AUTOSAR XML (schema 4-0-3)
package /ComponentTypes
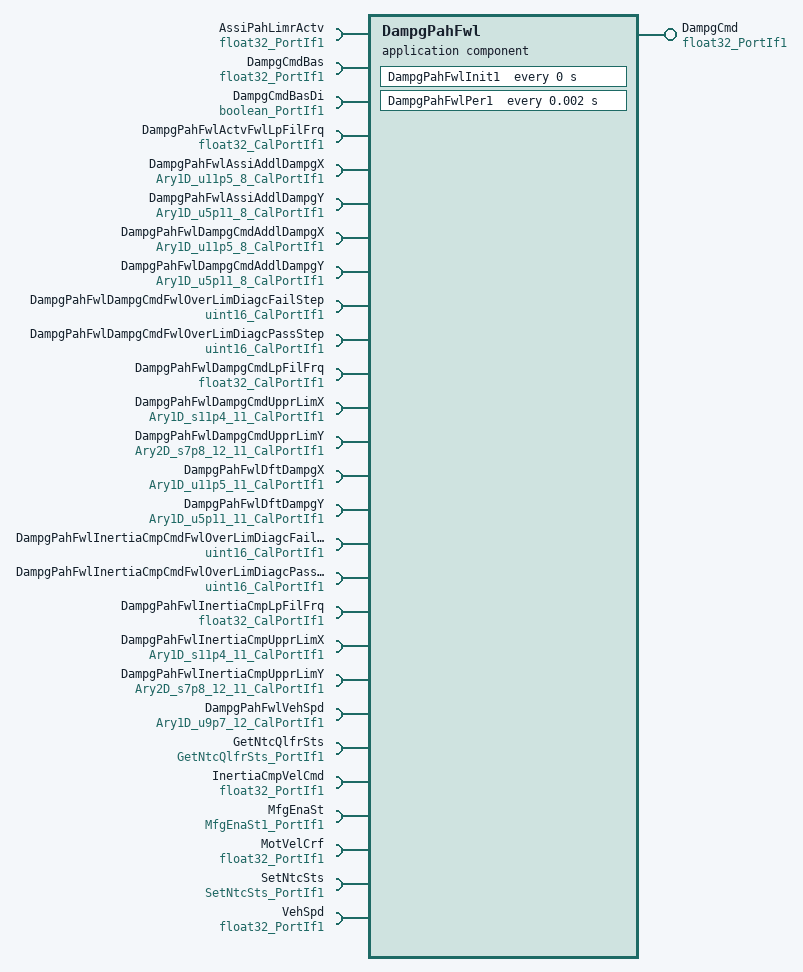
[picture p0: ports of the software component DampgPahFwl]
  application sw component type DampgPahFwl
    provide port DampgCmd: nonqueued-sender-com-spec{data-element=Val, init-value=0}, provided-interface=float32_PortIf1
    27 x require port:
      AssiPahLimrActv: nonqueued-receiver-com-spec{data-element=Val, filter=data-filter-type=ALWAYS, init-value=0}, required-interface=float32_PortIf1
      DampgCmdBas: nonqueued-receiver-com-spec{data-element=Val, filter=data-filter-type=ALWAYS, init-value=0}, required-interface=float32_PortIf1
      DampgCmdBasDi: nonqueued-receiver-com-spec{data-element=Logl, filter=data-filter-type=ALWAYS, init-value=0}, required-interface=boolean_PortIf1
      DampgPahFwlActvFwlLpFilFrq: parameter-require-com-spec{init-value=10, parameter=Val}, required-interface=float32_CalPortIf1
      DampgPahFwlAssiAddlDampgX: parameter-require-com-spec{init-value=[0, 3200, 6400, 9600, 12800, 25600, 32736, 35776], parameter=Ary1D}, required-interface=Ary1D_u11p5_8_CalPortIf1
      DampgPahFwlAssiAddlDampgY: parameter-require-com-spec{init-value=[0, 6144, 14336, 14336, 14336, 14336, 14336, 14336], parameter=Ary1D}, required-interface=Ary1D_u5p11_8_CalPortIf1
      DampgPahFwlDampgCmdAddlDampgX: parameter-require-com-spec{init-value=[0, 3200, 6400, 9600, 12800, 25600, 32736, 35776], parameter=Ary1D}, required-interface=Ary1D_u11p5_8_CalPortIf1
      DampgPahFwlDampgCmdAddlDampgY: parameter-require-com-spec{init-value=[0, 6144, 14336, 14336, 14336, 14336, 14336, 14336], parameter=Ary1D}, required-interface=Ary1D_u5p11_8_CalPortIf1
      DampgPahFwlDampgCmdFwlOverLimDiagcFailStep: parameter-require-com-spec{init-value=1311, parameter=Val}, required-interface=uint16_CalPortIf1
      DampgPahFwlDampgCmdFwlOverLimDiagcPassStep: parameter-require-com-spec{init-value=1311, parameter=Val}, required-interface=uint16_CalPortIf1
      DampgPahFwlDampgCmdLpFilFrq: parameter-require-com-spec{init-value=50, parameter=Val}, required-interface=float32_CalPortIf1
      DampgPahFwlDampgCmdUpprLimX: parameter-require-com-spec{init-value=[-9600, -1600, 0, 640, 1280, 1920, 3200, 4480, 5760, 7680, 9600], parameter=Ary1D}, required-interface=Ary1D_s11p4_11_CalPortIf1
      DampgPahFwlDampgCmdUpprLimY: parameter-require-com-spec{init-value=12 x 11 x 2253, parameter=Ary2D}, required-interface=Ary2D_s7p8_12_11_CalPortIf1
      DampgPahFwlDftDampgX: parameter-require-com-spec{init-value=[0, 1184, 2368, 3552, 4736, 5920, 7104, 8288, 9472, 10656, 11840], parameter=Ary1D}, required-interface=Ary1D_u11p5_11_CalPortIf1
      DampgPahFwlDftDampgY: parameter-require-com-spec{init-value=[0, 101, 232, 393, 586, 807, 1061, 1349, 1663, 2005, 2376], parameter=Ary1D}, required-interface=Ary1D_u5p11_11_CalPortIf1
      DampgPahFwlInertiaCmpCmdFwlOverLimDiagcFailStep: parameter-require-com-spec{init-value=1311, parameter=Val}, required-interface=uint16_CalPortIf1
      DampgPahFwlInertiaCmpCmdFwlOverLimDiagcPassStep: parameter-require-com-spec{init-value=1311, parameter=Val}, required-interface=uint16_CalPortIf1
      DampgPahFwlInertiaCmpLpFilFrq: parameter-require-com-spec{init-value=50, parameter=Val}, required-interface=float32_CalPortIf1
      DampgPahFwlInertiaCmpUpprLimX: parameter-require-com-spec{init-value=[-9600, -1600, 0, 640, 1280, 1920, 3200, 4480, 5760, 7680, 9600], parameter=Ary1D}, required-interface=Ary1D_s11p4_11_CalPortIf1
      DampgPahFwlInertiaCmpUpprLimY: parameter-require-com-spec{init-value=12 x 11 x 2253, parameter=Ary2D}, required-interface=Ary2D_s7p8_12_11_CalPortIf1
      DampgPahFwlVehSpd: parameter-require-com-spec{init-value=[0, 256, 1280, 3200, 6400, 9600, 12800, 19200, 25600, 31872, 32000, 32128], parameter=Ary1D}, required-interface=Ary1D_u9p7_12_CalPortIf1
      GetNtcQlfrSts: required-interface=GetNtcQlfrSts_PortIf1
      InertiaCmpVelCmd: nonqueued-receiver-com-spec{data-element=Val, filter=data-filter-type=ALWAYS, init-value=0}, required-interface=float32_PortIf1
      MfgEnaSt: nonqueued-receiver-com-spec{data-element=Val, filter=data-filter-type=ALWAYS, init-value=0}, required-interface=MfgEnaSt1_PortIf1
      MotVelCrf: nonqueued-receiver-com-spec{data-element=Val, filter=data-filter-type=ALWAYS, init-value=0}, required-interface=float32_PortIf1
      SetNtcSts: required-interface=SetNtcSts_PortIf1
      VehSpd: nonqueued-receiver-com-spec{data-element=Val, filter=data-filter-type=ALWAYS, init-value=0}, required-interface=float32_PortIf1
    behavior DampgPahFwl_InternalBehavior
      ar-typed-per-instance-memorys:
        19 x data, all with sw-calibration-access=READ-ONLY:
          DampgCmdLpFilLowrLim: type=FilLpRec1
          DampgCmdLpFilUpprLim: type=FilLpRec1
          DampgDecPrfmncPrev: type=boolean
          dDampgPahFwlActvRaw: type=float32
          dDampgPahFwlAddDampg: type=float32
          dDampgPahFwlDampgCmdLimd: type=float32
          dDampgPahFwlDampgCmdLowrLimFild: type=float32
          dDampgPahFwlDampgCmdOverLim: type=boolean
          dDampgPahFwlDampgCmdUpprLimFild: type=float32
          dDampgPahFwlInertiaCmpHpPah: type=float32
          dDampgPahFwlInertiaCmpLowrLimFild: type=float32
          dDampgPahFwlInertiaCmpLpLimd: type=float32
          dDampgPahFwlInertiaCmpLpPah: type=float32
          dDampgPahFwlInertiaCmpOverLim: type=boolean
          dDampgPahFwlInertiaCmpUpprLimFild: type=float32
          FwlActvLpFil: type=FilLpRec1
          InertiaCmpLpFil: type=FilLpRec1
          InertiaCmpLpFilLowrLim: type=FilLpRec1
          InertiaCmpLpFilUpprLim: type=FilLpRec1
      timing event DampgPahFwl_InitEvent: start-on-event=DampgPahFwlInit1, period=0
      timing event TMT_DampgPahFwlPer1: start-on-event=DampgPahFwlPer1, period=0.002
      runnable DampgPahFwlInit1
        sync call SC_SetNtcSts_Oper: operation=SetNtcSts.Oper, timeout=0
      runnable DampgPahFwlPer1
        data-receive-point-by-arguments:
          7 x access:
            REC_AssiPahLimrActv_Val: accessed-variable=AssiPahLimrActv.Val
            REC_DampgCmdBas_Val: accessed-variable=DampgCmdBas.Val
            REC_DampgCmdBasDi_Logl: accessed-variable=DampgCmdBasDi.Logl
            REC_InertiaCmpVelCmd_Val: accessed-variable=InertiaCmpVelCmd.Val
            REC_MfgEnaSt_Val: accessed-variable=MfgEnaSt.Val
            REC_MotVelCrf_Val: accessed-variable=MotVelCrf.Val
            REC_VehSpd_Val: accessed-variable=VehSpd.Val
        data-send-points:
          access SEND_DampgCmd_Val: accessed-variable=DampgCmd.Val
        sync call SC_GetNtcQlfrSts_Oper: operation=GetNtcQlfrSts.Oper, timeout=0
        sync call SC_SetNtcSts_Oper: operation=SetNtcSts.Oper, timeout=0
  swc implementation DampgPahFwl_Implementation: behavior=DampgPahFwl_InternalBehavior
    code-descriptors:
      code Default: artifact-descriptors=autosar-engineering-object={short-label=Default, category=SWSRC}
